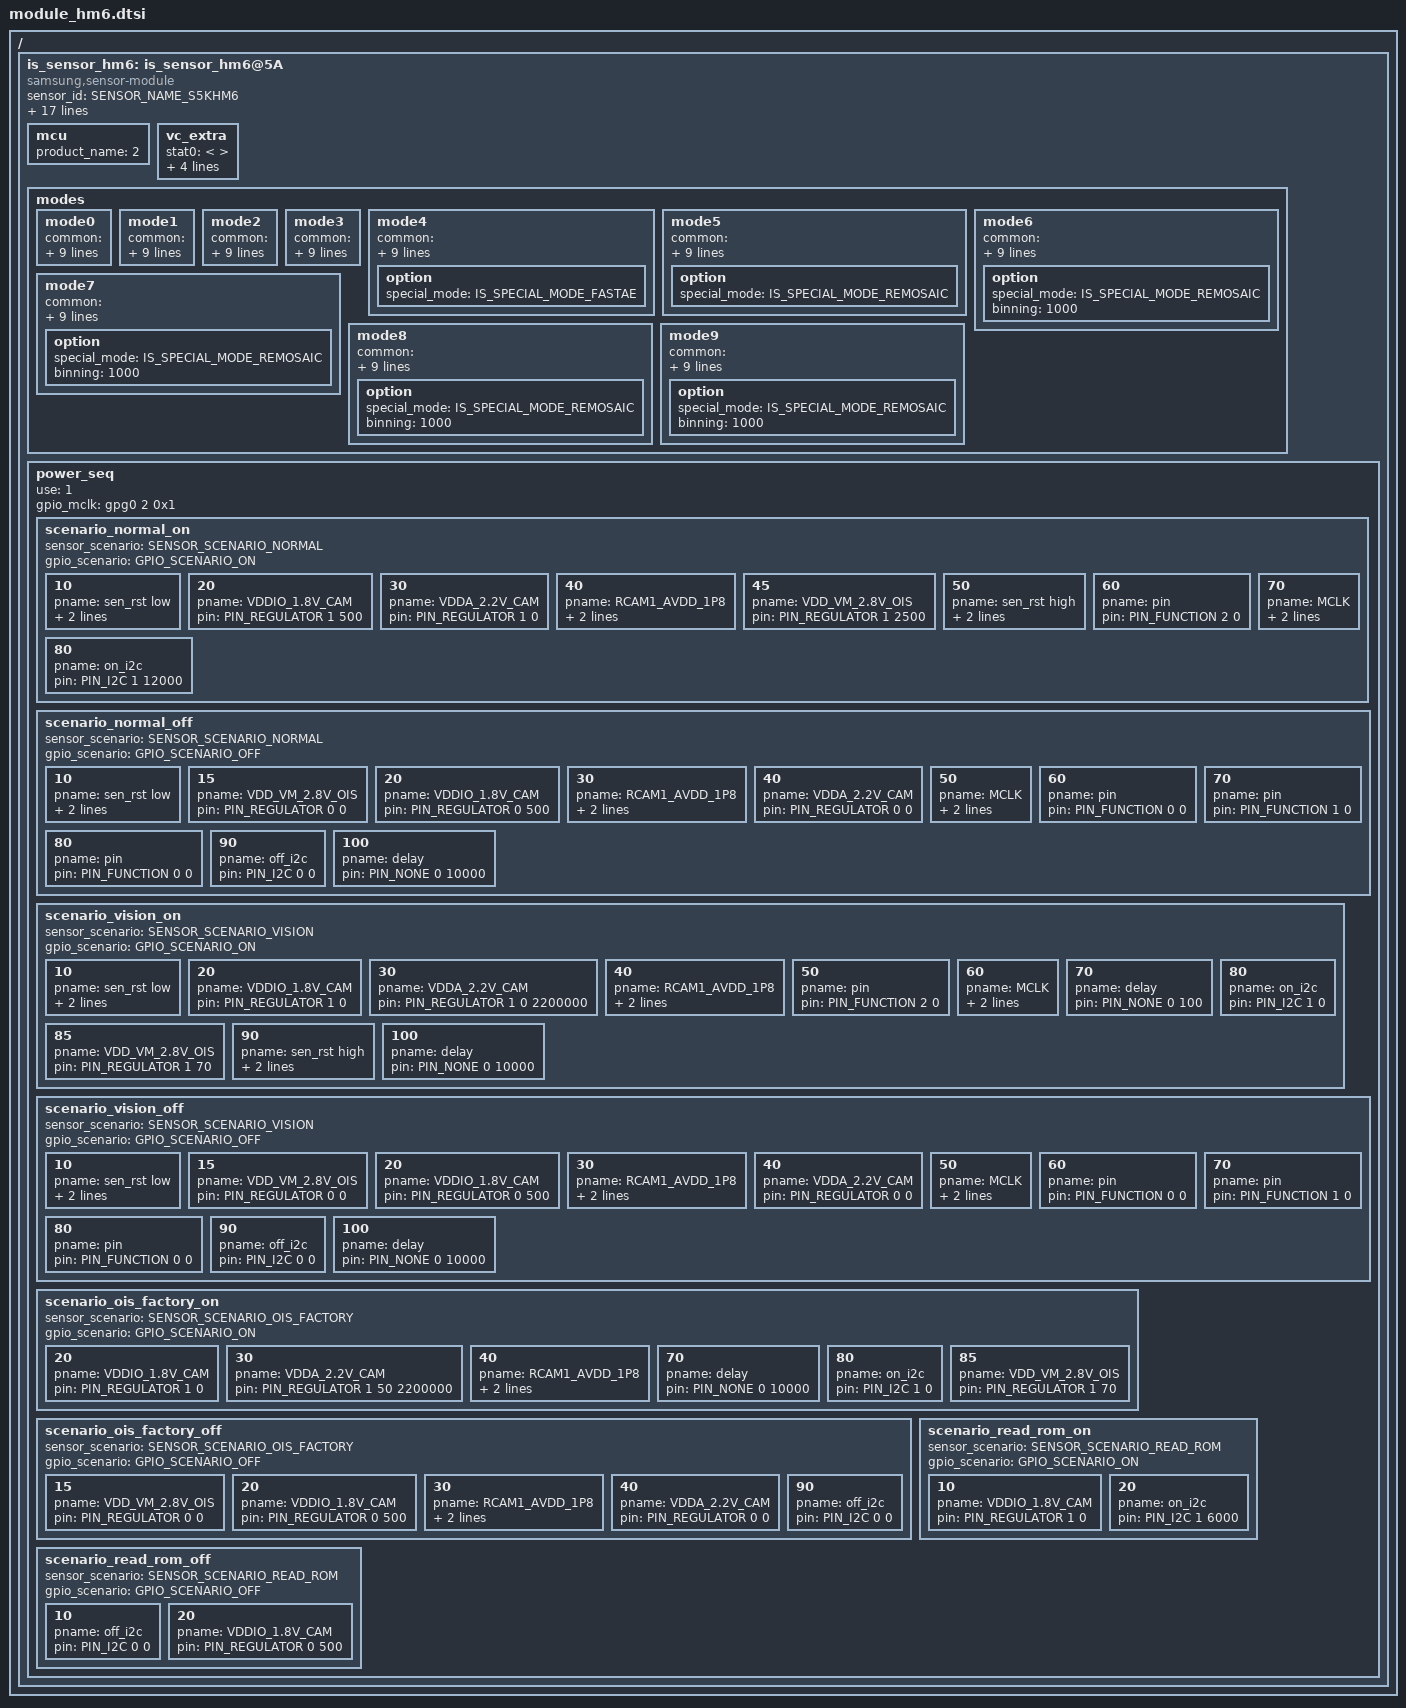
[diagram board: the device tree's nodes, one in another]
/*
 * SAMSUNG EXYNOSxxxx board camera device tree source
 *
 * Copyright (c) 2022 Samsung Electronics Co., Ltd.
 *		http://www.samsung.com
 *
 * This program is free software; you can redistribute it and/or modify
 * it under the terms of the GNU General Public License version 2 as
 * published by the Free Software Foundation.
 */

#include <dt-bindings/camera/exynos_is_dt.h>

/ {
	fragment@camera {
		target-path = "/";
		__overlay__ {
			is_sensor_hm6: is_sensor_hm6@5A {
				compatible = "samsung,sensor-module";

				/* common */
				sensor_id = <SENSOR_NAME_S5KHM6>;
				active_width = <12000>;
				active_height = <9000>;
				margin_left = <0>;
				margin_right = <0>;
				margin_top = <0>;
				margin_bottom = <0>;
				max_framerate = <240>;
				bitwidth = <10>;
				use_retention_mode = <SENSOR_RETENTION_INACTIVE>;
				sensor_maker = "SLSI";
				sensor_name = "S5KHM6";
				setfile_name = "setfile_hm6.bin";
				pinning_setfile;
				preload_setfile;

				status = "okay";

				/* vendor */
				rom_type = <2>; /* ROM_TYPE_EEPROM */
				rom_id = <0>;
				rom_cal_index = <0>;

				mcu {
					product_name = <2>; /* INTERNAL */
				};

				vc_extra {
					/* ex) statX = <stat_type, sensor_mode, max_width, max_height, max_element> */
					stat0 = </* not available */>;									/* VC_BUF_DATA_TYPE_SENSOR_STAT1 */
					stat1 = </*VC_STAT_TYPE_PDP_4_1_PDAF_STAT0*/ 1200 /*VC_SENSOR_MODE_2PD_MODE3*/ 102 4000 750 2>;	/* VC_BUF_DATA_TYPE_GENERAL_STAT1 */
					stat2 = </* not available */>;									/* VC_BUF_DATA_TYPE_SENSOR_STAT2 */
					stat3 = </*VC_STAT_TYPE_PDP_4_1_PDAF_STAT1*/ 1201 /*VC_SENSOR_MODE_2PD_MODE3*/ 102 4000 750 2>;	/* VC_BUF_DATA_TYPE_GENERAL_STAT2 */
					stat_vc = <2>; /* STAT out VC after CSIS link */
				};


				modes {
					/* common = <width, height, fps, settle, mode, lane, speed, interleave, lrte, pd_mode> */
					/* vcX = <map, hwformat, width, height, hwformat, type, width, height> */
					mode0 { /* SENSOR_HM6_4000X3000_30FPS */
						common = <4000 3000 30 0 0 CSI_DATA_LANES_3 2022 CSI_MODE_VC_ONLY LRTE_DISABLE PD_MOD3>;
						vc0 = </* in */ 0 HW_FORMAT_RAW10 4000 3000	/* out */ HW_FORMAT_RAW10 VC_NOTHING 4000 3000>;
						vc1 = </* in */ 2 HW_FORMAT_UNKNOWN 0 0		/* out */ HW_FORMAT_UNKNOWN VC_NOTHING 0 0>;
						vc2 = </* in */ 1 HW_FORMAT_RAW10_POTF 4000 750	/* out */ HW_FORMAT_RAW10 VC_NOTHING 0 0>;
						vc3 = </* in */ 3 HW_FORMAT_UNKNOWN 0 0		/* out */ HW_FORMAT_UNKNOWN VC_NOTHING 0 0>;
					};
					mode1 { /* SENSOR_HM6_4000X2252_30FPS */
						common = <4000 2252 30 0 1 CSI_DATA_LANES_3 2022 CSI_MODE_VC_ONLY LRTE_DISABLE PD_MOD3>;
						vc0 = </* in */ 0 HW_FORMAT_RAW10 4000 2252	/* out */ HW_FORMAT_RAW10 VC_NOTHING 4000 2252>;
						vc1 = </* in */ 2 HW_FORMAT_UNKNOWN 0 0		/* out */ HW_FORMAT_UNKNOWN VC_NOTHING 0 0>;
						vc2 = </* in */ 1 HW_FORMAT_RAW10_POTF 4000 562	/* out */ HW_FORMAT_RAW10 VC_NOTHING 0 0>;
						vc3 = </* in */ 3 HW_FORMAT_UNKNOWN 0 0		/* out */ HW_FORMAT_UNKNOWN VC_NOTHING 0 0>;
					};
					mode2 { /* SENSOR_HM6_4000X2252_60FPS */
						common = <4000 2252 60 0 2 CSI_DATA_LANES_3 2022 CSI_MODE_VC_ONLY LRTE_DISABLE PD_MOD3>;
						vc0 = </* in */ 0 HW_FORMAT_RAW10 4000 2252	/* out */ HW_FORMAT_RAW10 VC_NOTHING 4000 2252>;
						vc1 = </* in */ 2 HW_FORMAT_UNKNOWN 0 0		/* out */ HW_FORMAT_UNKNOWN VC_NOTHING 0 0>;
						vc2 = </* in */ 1 HW_FORMAT_RAW10_POTF 4000 562	/* out */ HW_FORMAT_RAW10 VC_NOTHING 0 0>;
						vc3 = </* in */ 3 HW_FORMAT_UNKNOWN 0 0		/* out */ HW_FORMAT_UNKNOWN VC_NOTHING 0 0>;
					};
					mode3 { /* SENSOR_HM6_1280X720_240FPS */
						common = <1280 720 240 0 3 CSI_DATA_LANES_3 2022 CSI_MODE_VC_ONLY LRTE_DISABLE PD_MOD3>;
						vc0 = </* in */ 0 HW_FORMAT_RAW10 1280 720	/* out */ HW_FORMAT_RAW10 VC_NOTHING 1280 720>;
						vc1 = </* in */ 2 HW_FORMAT_UNKNOWN 0 0		/* out */ HW_FORMAT_UNKNOWN VC_NOTHING 0 0>;
						vc2 = </* in */ 1 HW_FORMAT_RAW10_POTF 1280 180	/* out */ HW_FORMAT_RAW10 VC_NOTHING 0 0>;
						vc3 = </* in */ 3 HW_FORMAT_UNKNOWN 0 0		/* out */ HW_FORMAT_UNKNOWN VC_NOTHING 0 0>;
					};
					mode4 { /* SENSOR_HM6_2000X1500_120FPS */
						common = <2000 1500 120 0 4 CSI_DATA_LANES_3 2022 CSI_MODE_VC_ONLY LRTE_DISABLE PD_MOD3>;
						vc0 = </* in */ 0 HW_FORMAT_RAW10 2000 1500	/* out */ HW_FORMAT_RAW10 VC_NOTHING 2000 1500>;
						vc1 = </* in */ 2 HW_FORMAT_UNKNOWN 0 0		/* out */ HW_FORMAT_UNKNOWN VC_NOTHING 0 0>;
						vc2 = </* in */ 1 HW_FORMAT_RAW10_POTF 2000 374	/* out */ HW_FORMAT_RAW10 VC_NOTHING 0 0>;
						vc3 = </* in */ 3 HW_FORMAT_UNKNOWN 0 0		/* out */ HW_FORMAT_UNKNOWN VC_NOTHING 0 0>;
						option { special_mode = <IS_SPECIAL_MODE_FASTAE>; };
					};
					mode5 { /* SENSOR_HM6_12000X9000_8FPS */
						common = <12000 9000 8 0 5 CSI_DATA_LANES_3 2022 CSI_MODE_VC_ONLY LRTE_DISABLE PD_NONE>;
						vc0 = </* in */ 0 HW_FORMAT_RAW10 12000 9000	/* out */ HW_FORMAT_RAW10 VC_NOTHING 12000 9000>;
						vc1 = </* in */ 1 HW_FORMAT_UNKNOWN 0 0		/* out */ HW_FORMAT_UNKNOWN VC_NOTHING 0 0>;
						vc2 = </* in */ 2 HW_FORMAT_UNKNOWN 0 0		/* out */ HW_FORMAT_UNKNOWN VC_NOTHING 0 0>;
						vc3 = </* in */ 3 HW_FORMAT_UNKNOWN 0 0		/* out */ HW_FORMAT_UNKNOWN VC_NOTHING 0 0>;
						option { special_mode = <IS_SPECIAL_MODE_REMOSAIC>; };
					};
					mode6 { /* SENSOR_HM6_6000X4500_18FPS_REMOSAIC_LN2 */
						common = <6000 4500 18 0 6 CSI_DATA_LANES_3 2022 CSI_MODE_VC_ONLY LRTE_DISABLE PD_NONE EX_LOW_RES_TETRA>;
						vc0 = </* in */ 0 HW_FORMAT_RAW10 6000 4500	/* out */ HW_FORMAT_RAW10 VC_NOTHING 6000 4500>;
						vc1 = </* in */ 1 HW_FORMAT_UNKNOWN 0 0		/* out */ HW_FORMAT_UNKNOWN VC_NOTHING 0 0>;
						vc2 = </* in */ 2 HW_FORMAT_UNKNOWN 0 0		/* out */ HW_FORMAT_UNKNOWN VC_NOTHING 0 0>;
						vc3 = </* in */ 3 HW_FORMAT_UNKNOWN 0 0		/* out */ HW_FORMAT_UNKNOWN VC_NOTHING 0 0>;
						option { special_mode = <IS_SPECIAL_MODE_REMOSAIC>; binning = <1000>; };
					};
					mode7 { /* SENSOR_HM6_6000X3376_24FPS */
						common = <6000 3376 24 0 7 CSI_DATA_LANES_3 2022 CSI_MODE_VC_ONLY LRTE_DISABLE PD_NONE>;
						vc0 = </* in */ 0 HW_FORMAT_RAW10 6000 3376	/* out */ HW_FORMAT_RAW10 VC_NOTHING 6000 3376>;
						vc1 = </* in */ 1 HW_FORMAT_UNKNOWN 0 0		/* out */ HW_FORMAT_UNKNOWN VC_NOTHING 0 0>;
						vc2 = </* in */ 2 HW_FORMAT_UNKNOWN 0 0		/* out */ HW_FORMAT_UNKNOWN VC_NOTHING 0 0>;
						vc3 = </* in */ 3 HW_FORMAT_UNKNOWN 0 0		/* out */ HW_FORMAT_UNKNOWN VC_NOTHING 0 0>;
						option { special_mode = <IS_SPECIAL_MODE_REMOSAIC>; binning = <1000>; };
					};
					mode8 { /* SENSOR_HM6_4000x3000_16FPS_REMOSAIC_LN2 */
						common = <4000 3000 16 0 8 CSI_DATA_LANES_3 2022 CSI_MODE_VC_ONLY LRTE_DISABLE PD_NONE EX_LOW_RES_TETRA>;
						vc0 = </* in */ 0 HW_FORMAT_RAW10 4000 3000	/* out */ HW_FORMAT_RAW10 VC_NOTHING 4000 3000>;
						vc1 = </* in */ 1 HW_FORMAT_UNKNOWN 0 0		/* out */ HW_FORMAT_UNKNOWN VC_NOTHING 0 0>;
						vc2 = </* in */ 2 HW_FORMAT_UNKNOWN 0 0		/* out */ HW_FORMAT_UNKNOWN VC_NOTHING 0 0>;
						vc3 = </* in */ 3 HW_FORMAT_UNKNOWN 0 0		/* out */ HW_FORMAT_UNKNOWN VC_NOTHING 0 0>;
						option { special_mode = <IS_SPECIAL_MODE_REMOSAIC>; binning = <1000>; };
					};
					mode9 { /* SENSOR_HM6_4000x2252_34FPS_REMOSAIC_LN2 */
						common = <4000 2252 34 0 9 CSI_DATA_LANES_3 2022 CSI_MODE_VC_ONLY LRTE_DISABLE PD_NONE EX_LOW_RES_TETRA>;
						vc0 = </* in */ 0 HW_FORMAT_RAW10 4000 2252	/* out */ HW_FORMAT_RAW10 VC_NOTHING 4000 2252>;
						vc1 = </* in */ 1 HW_FORMAT_UNKNOWN 0 0		/* out */ HW_FORMAT_UNKNOWN VC_NOTHING 0 0>;
						vc2 = </* in */ 2 HW_FORMAT_UNKNOWN 0 0		/* out */ HW_FORMAT_UNKNOWN VC_NOTHING 0 0>;
						vc3 = </* in */ 3 HW_FORMAT_UNKNOWN 0 0		/* out */ HW_FORMAT_UNKNOWN VC_NOTHING 0 0>;
						option { special_mode = <IS_SPECIAL_MODE_REMOSAIC>; binning = <1000>; };
					};
				};

				power_seq {
					use = <1>;
					gpio_mclk = <&gpg0 2 0x1>;

					scenario_normal_on {
						sensor_scenario = <SENSOR_SCENARIO_NORMAL>;
						gpio_scenario = <GPIO_SCENARIO_ON>;

						/* A start node number should be over the 10 for reserved number 0~9. */
						/* pname = "name"; pin = <act value delay voltage>; gpio = <gpx# # 0x1>; */
						10 { pname = "sen_rst low";     pin = <PIN_OUTPUT 0 500>; gpio = <&gpg1 1 0x1>; };
						20 { pname = "VDDIO_1.8V_CAM";  pin = <PIN_REGULATOR 1 500>; };
						30 { pname = "VDDA_2.2V_CAM";   pin = <PIN_REGULATOR 1 0>; };
						40 { pname = "RCAM1_AVDD_1P8";  pin = <PIN_OUTPUT 1 0>; gpio = <&gpm12 0 0x1>; };  /* AFVDD, DVDD */
						45 { pname = "VDD_VM_2.8V_OIS"; pin = <PIN_REGULATOR 1 2500>; };
						50 { pname = "sen_rst high";    pin = <PIN_OUTPUT 1 500>; gpio = <&gpg1 1 0x1>; };
						60 { pname = "pin";             pin = <PIN_FUNCTION 2 0>; };
						70 { pname = "MCLK";            pin = <PIN_MCLK 1 1000>; gpio = <&gpg0 2 0x1>; };
						80 { pname = "on_i2c";          pin = <PIN_I2C 1 12000>; };
					};

					scenario_normal_off {
						sensor_scenario = <SENSOR_SCENARIO_NORMAL>;
						gpio_scenario = <GPIO_SCENARIO_OFF>;

						/* A start node number should be over the 10 for reserved number 0~9. */
						/* pname = "name"; pin = <act value delay voltage>; gpio = <gpx# # 0x1>; */
						10 { pname = "sen_rst low"; pin = <PIN_OUTPUT 0 500>; gpio = <&gpg1 1 0x1>; };
						15 { pname = "VDD_VM_2.8V_OIS"; pin = <PIN_REGULATOR 0 0>; };
						20 { pname = "VDDIO_1.8V_CAM"; pin = <PIN_REGULATOR 0 500>; };
						30 { pname = "RCAM1_AVDD_1P8"; pin = <PIN_OUTPUT 0 0>; gpio = <&gpm12 0 0x1>; };
						40 { pname = "VDDA_2.2V_CAM"; pin = <PIN_REGULATOR 0 0>; };
						50 { pname = "MCLK"; pin = <PIN_MCLK 0 500>; gpio = <&gpg0 2 0x1>; };
						60 { pname = "pin"; pin = <PIN_FUNCTION 0 0>; };
						70 { pname = "pin"; pin = <PIN_FUNCTION 1 0>; };
						80 { pname = "pin"; pin = <PIN_FUNCTION 0 0>; };
						90 { pname = "off_i2c"; pin = <PIN_I2C 0 0>; };
						100 { pname = "delay"; pin = <PIN_NONE 0 10000>; };
					};

					scenario_vision_on {
						sensor_scenario = <SENSOR_SCENARIO_VISION>;
						gpio_scenario = <GPIO_SCENARIO_ON>;

						/* A start node number should be over the 10 for reserved number 0~9. */
						/* pname = "name"; pin = <act value delay voltage>; gpio = <gpx# # 0x1>; */
						10 { pname = "sen_rst low"; pin = <PIN_OUTPUT 0 0>; gpio = <&gpg1 1 0x1>; };
						20 { pname = "VDDIO_1.8V_CAM"; pin = <PIN_REGULATOR 1 0>; };
						30 { pname = "VDDA_2.2V_CAM"; pin = <PIN_REGULATOR 1 0 2200000>; };
						40 { pname = "RCAM1_AVDD_1P8"; pin = <PIN_OUTPUT 1 0>; gpio = <&gpm12 0 0x1>; };
						50 { pname = "pin"; pin = <PIN_FUNCTION 2 0>; };
						60 { pname = "MCLK"; pin = <PIN_MCLK 1 0>; gpio = <&gpg0 2 0x1>; };
						70 { pname = "delay"; pin = <PIN_NONE 0 100>; };
						80 { pname = "on_i2c"; pin = <PIN_I2C 1 0>; };
						85 { pname = "VDD_VM_2.8V_OIS"; pin = <PIN_REGULATOR 1 70>; };
						90 { pname = "sen_rst high"; pin = <PIN_OUTPUT 1 50>; gpio = <&gpg1 1 0x1>; };
						100 { pname = "delay"; pin = <PIN_NONE 0 10000>; };
					};

					scenario_vision_off {
						sensor_scenario = <SENSOR_SCENARIO_VISION>;
						gpio_scenario = <GPIO_SCENARIO_OFF>;

						/* A start node number should be over the 10 for reserved number 0~9. */
						/* pname = "name"; pin = <act value delay voltage>; gpio = <gpx# # 0x1>; */
						10 { pname = "sen_rst low"; pin = <PIN_OUTPUT 0 500>; gpio = <&gpg1 1 0x1>; };
						15 { pname = "VDD_VM_2.8V_OIS"; pin = <PIN_REGULATOR 0 0>; };
						20 { pname = "VDDIO_1.8V_CAM"; pin = <PIN_REGULATOR 0 500>; };
						30 { pname = "RCAM1_AVDD_1P8"; pin = <PIN_OUTPUT 0 0>; gpio = <&gpm12 0 0x1>; };
						40 { pname = "VDDA_2.2V_CAM"; pin = <PIN_REGULATOR 0 0>; };
						50 { pname = "MCLK"; pin = <PIN_MCLK 0 500>; gpio = <&gpg0 2 0x1>; };
						60 { pname = "pin"; pin = <PIN_FUNCTION 0 0>; };
						70 { pname = "pin"; pin = <PIN_FUNCTION 1 0>; };
						80 { pname = "pin"; pin = <PIN_FUNCTION 0 0>; };
						90 { pname = "off_i2c"; pin = <PIN_I2C 0 0>; };
						100 { pname = "delay"; pin = <PIN_NONE 0 10000>; };
					};

					scenario_ois_factory_on {
						sensor_scenario = <SENSOR_SCENARIO_OIS_FACTORY>;
						gpio_scenario = <GPIO_SCENARIO_ON>;

						/* A start node number should be over the 10 for reserved number 0~9. */
						/* pname = "name"; pin = <act value delay voltage>; gpio = <gpx# # 0x1>; */
						20 { pname = "VDDIO_1.8V_CAM"; pin = <PIN_REGULATOR 1 0>; };
						30 { pname = "VDDA_2.2V_CAM"; pin = <PIN_REGULATOR 1 50 2200000>; };
						40 { pname = "RCAM1_AVDD_1P8"; pin = <PIN_OUTPUT 1 0>; gpio = <&gpm12 0 0x1>; };
						70 { pname = "delay"; pin = <PIN_NONE 0 10000>; };
						80 { pname = "on_i2c"; pin = <PIN_I2C 1 0>; };
						85 { pname = "VDD_VM_2.8V_OIS"; pin = <PIN_REGULATOR 1 70>; };
					};

					scenario_ois_factory_off {
						sensor_scenario = <SENSOR_SCENARIO_OIS_FACTORY>;
						gpio_scenario = <GPIO_SCENARIO_OFF>;

						/* A start node number should be over the 10 for reserved number 0~9. */
						/* pname = "name"; pin = <act value delay voltage>; gpio = <gpx# # 0x1>; */
						15 { pname = "VDD_VM_2.8V_OIS"; pin = <PIN_REGULATOR 0 0>; };
						20 { pname = "VDDIO_1.8V_CAM"; pin = <PIN_REGULATOR 0 500>; };
						30 { pname = "RCAM1_AVDD_1P8"; pin = <PIN_OUTPUT 0 0>; gpio = <&gpm12 0 0x1>; };
						40 { pname = "VDDA_2.2V_CAM"; pin = <PIN_REGULATOR 0 0>; };
						90 { pname = "off_i2c"; pin = <PIN_I2C 0 0>; };
					};

					scenario_read_rom_on {
						sensor_scenario = <SENSOR_SCENARIO_READ_ROM>;
						gpio_scenario = <GPIO_SCENARIO_ON>;

						/* A start node number should be over the 10 for reserved number 0~9. */
						/* pname = "name"; pin = <act value delay voltage>; gpio = <gpx# # 0x1>; */
						10 { pname = "VDDIO_1.8V_CAM"; pin = <PIN_REGULATOR 1 0>; };
						20 { pname = "on_i2c"; pin = <PIN_I2C 1 6000>; };
					};

					scenario_read_rom_off {
						sensor_scenario = <SENSOR_SCENARIO_READ_ROM>;
						gpio_scenario = <GPIO_SCENARIO_OFF>;

						/* A start node number should be over the 10 for reserved number 0~9. */
						/* pname = "name"; pin = <act value delay voltage>; gpio = <gpx# # 0x1>; */
						10 { pname = "off_i2c"; pin = <PIN_I2C 0 0>; };
						20 { pname = "VDDIO_1.8V_CAM"; pin = <PIN_REGULATOR 0 500>; };
					};
				};
			};
		}; /* end of __overlay__ */
	}; /* end of fragment */
}; /* end of root */
